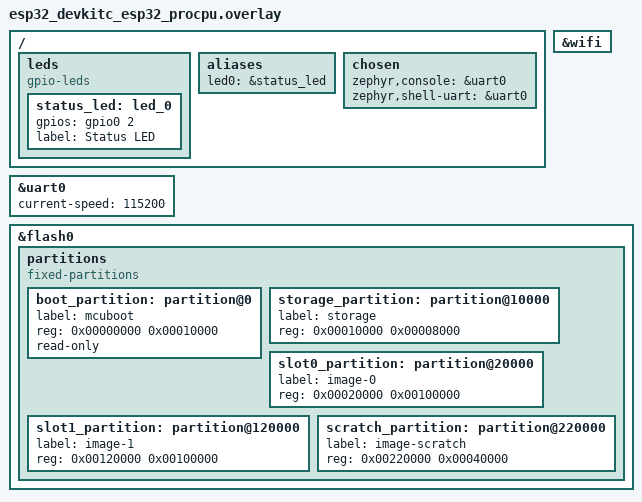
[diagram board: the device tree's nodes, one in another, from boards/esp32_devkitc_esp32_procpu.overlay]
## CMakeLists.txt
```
# SPDX-License-Identifier: Apache-2.0

cmake_minimum_required(VERSION 3.20.0)

find_package(Zephyr REQUIRED HINTS $ENV{ZEPHYR_BASE})
#find_package(Sysbuild REQUIRED)
#project(sample_with_mcuboot)

# Verify that this sample is built through sysbuild to ensure MCUboot is
# automatically included and that sample specific MCUboot configurations are
# used when building MCUboot.
test_sysbuild()

project(zephyr_project)
add_subdirectory(app)
#add_subdirectory(sysbuild/mcuboot mcuboot)
```

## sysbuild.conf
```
# Enable MCUboot
SB_CONFIG_BOOTLOADER_MCUBOOT=y

# Sign images automatically
SB_CONFIG_BOOT_SIGNATURE_TYPE_RSA=y
#SB_CONFIG_BOOT_SIGNATURE_KEY_FILE="peter_pan.pem"

#CONFIG_BOOT_SIGNATURE_KEY_FILE="peter_pan.pem"
```

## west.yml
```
manifest:
  defaults:
    remote: upstream
  remotes:
    - name: upstream
      url-base: https://github.com/zephyrproject-rtos
    - name: mcuboot
      url-base: https://github.com/mcu-tools
  projects:
    - name: zephyr
      remote: upstream
      revision: main
      import: true
    - name: mcuboot
      remote: mcuboot
      revision: main  # oder v2.1.0 für stabile Version
      path: bootloader/mcuboot
    - name: tinycrypt
      path: modules/crypto/tinycrypt
      remote: mcu-tools
      revision: main
```

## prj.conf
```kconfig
# Empty file
# CONFIG_PARTITION_MANAGER=n
```

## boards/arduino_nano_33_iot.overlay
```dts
// Device tree overlay for Arduino Nano 33 IoT

&flash0 {
    partitions {
        compatible = "fixed-partitions";
        #address-cells = <1>;
        #size-cells = <1>;

        boot_partition: partition@0 {
            label = "mcuboot";
            reg = <0x00000000 0x8000>;
        };
        
        slot0_partition: partition@8000 {
            label = "image-0";
            reg = <0x00008000 0x74000>;
        };
        
        slot1_partition: partition@7c000 {
            label = "image-1";
            reg = <0x0007c000 0x74000>;
        };
        
        scratch_partition: partition@f0000 {
            label = "image-scratch";
            reg = <0x000f0000 0x10000>;
        };
    };
};

/ {
    aliases {
        led0 = &led0;
        sw0 = &button0;
    };

    leds {
        compatible = "gpio-leds";
        led0: led_0 {
            gpios = <&porta 17 GPIO_ACTIVE_LOW>;
            label = "Yellow LED";
        };
    };

    buttons {
        compatible = "gpio-keys";
        button0: button_0 {
            gpios = <&porta 16 (GPIO_PULL_UP | GPIO_ACTIVE_LOW)>;
            label = "Push button switch";
        };
    };
};
```

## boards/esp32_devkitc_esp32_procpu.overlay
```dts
/ {
    leds {
        compatible = "gpio-leds";
        status_led: led_0 {
            gpios = <&gpio0 2 GPIO_ACTIVE_HIGH>;
            label = "Status LED";
        };
    };

    aliases {
        led0 = &status_led;
    };

    chosen {
        zephyr,console = &uart0;
        zephyr,shell-uart = &uart0;
    };
};

&uart0 {
    status = "okay";
    current-speed = <115200>;
};

&wifi {
    status = "okay";
};

/* Flash partitioning for OTA */
&flash0 {
    /delete-node/ partitions;
    partitions {
        compatible = "fixed-partitions";
        #address-cells = <1>;
        #size-cells = <1>;

        /* MCUboot bootloader - 64KB */
        boot_partition: partition@0 {
            label = "mcuboot";
            reg = <0x00000000 0x00010000>;
            read-only;
        };

        /* Storage partition - 32KB, aligned to 4KB boundary */
        storage_partition: partition@10000 {
            label = "storage";
            reg = <0x00010000 0x00008000>;
        };

        /* Application slot 0 - 1MB, aligned to 4KB boundary */
        slot0_partition: partition@20000 {
            label = "image-0";
            reg = <0x00020000 0x00100000>;
        };

        /* Application slot 1 - 1MB, aligned to 4KB boundary */
        slot1_partition: partition@120000 {
            label = "image-1";
            reg = <0x00120000 0x00100000>;
        };

        /* Scratch partition - 256KB, aligned to 4KB boundary */
        scratch_partition: partition@220000 {
            label = "image-scratch";
            reg = <0x00220000 0x00040000>;
        };
    };
};
```

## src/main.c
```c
#include <zephyr/kernel.h>
#include <zephyr/logging/log.h>
#include <zephyr/dfu/mcuboot.h>

#include "app_config.h"
#include "blinky.h"
#include "wifi_mgmt.h"
#include "ota_mgmt.h"

LOG_MODULE_REGISTER(main, LOG_LEVEL_INF);

// Define a work item for the delayed confirmation
static void confirm_work_handler(struct k_work *work);
static K_WORK_DELAYABLE_DEFINE(confirm_work, confirm_work_handler);

static void confirm_work_handler(struct k_work *work)
{
    LOG_INF("Confirming running firmware as valid.");
    if (boot_write_img_confirmed() != 0) {
        LOG_ERR("Failed to confirm image!");
    } else {
        LOG_INF("Image confirmed.");
    }
}

/* OTA status callback */
static void ota_status_changed(ota_status_t status)
{
    switch (status) {
    case OTA_STATUS_CHECKING:
        LOG_INF("OTA: Checking for updates...");
        break;
    case OTA_STATUS_UPDATE_AVAILABLE:
        LOG_INF("OTA: Update available, preparing download");
        break;
    case OTA_STATUS_DOWNLOADING:
        LOG_INF("OTA: Downloading firmware update");
        break;
    case OTA_STATUS_DOWNLOAD_COMPLETE:
        LOG_INF("OTA: Download complete, preparing to apply");
        break;
    case OTA_STATUS_APPLYING:
        LOG_INF("OTA: Applying update, device will reboot");
        break;
    case OTA_STATUS_ERROR:
        LOG_ERR("OTA: Error occurred, code: %d", ota_get_last_error());
        break;
    default:
        break;
    }
}

int main(void)
{
    char version[16];
    ota_get_current_version(version, sizeof(version));
    
    // ... initializations ...
    LOG_INF("Starting ESP32 Blinky OTA v%s", version);
    
    // Check for confirmation status right away
    if (boot_is_img_confirmed() == 0) {
        LOG_INF("Running new firmware in TEST mode. Scheduling confirmation in 30s.");
        k_work_schedule(&confirm_work, K_SECONDS(30));
    }

    // Initialize your subsystems AFTER the check
    ota_register_status_callback(ota_status_changed);
    // The ota_mgmt_init will be called by SYS_INIT

    LOG_INF("Main loop");
    while (1) {
        k_sleep(K_SECONDS(5));
        
        char ip_str[16];
        int result = wifi_get_ip_address_public(ip_str, sizeof(ip_str));
        if (result == 0) {
            LOG_INF("IP: %s", ip_str);
        } else {
            LOG_INF("No IP");
        }
    }
    
    return 0;
}
```

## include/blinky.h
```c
#ifndef BLINKY_H
#define BLINKY_H

#include <zephyr/kernel.h>

/* Blink interval in milliseconds */
#define BLINK_INTERVAL_MS 1000

/**
 * @brief Initialize LED subsystem
 * 
 * This function is called automatically during system initialization.
 * 
 * @return 0 on success, negative error code on failure
 */
int blinky_init(void);

#endif /* BLINKY_H */
```

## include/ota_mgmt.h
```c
#ifndef OTA_MGMT_H
#define OTA_MGMT_H

#include <zephyr/kernel.h>
#include <stdint.h>
#include <stdbool.h>

#ifdef __cplusplus
extern "C" {
#endif

/**
 * @brief Initialize OTA management subsystem
 * 
 * This function is called automatically during system initialization.
 * 
 * @return 0 on success, negative error code on failure
 */
int ota_mgmt_init(void);

#ifdef __cplusplus
}
#endif

#endif /* OTA_MGMT_H */
```

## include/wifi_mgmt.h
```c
#ifndef WIFI_MGMT_H
#define WIFI_MGMT_H

#include <stdbool.h>

#ifdef __cplusplus
extern "C" {
#endif

/**
 * @brief Check if WiFi is connected
 * 
 * @return true if WiFi is connected, false otherwise
 */
bool wifi_is_connected(void);

int wifi_get_ip_address_public(char *ip_str, size_t len);

#ifdef __cplusplus
}
#endif

#endif /* WIFI_MGMT_H */
```

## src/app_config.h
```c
#ifndef APP_CONFIG_H
#define APP_CONFIG_H

/* Application Configuration */
#define APP_NAME "ESP32_BLINKY_OTA"
#define APP_VERSION_MAJOR 1
#define APP_VERSION_MINOR 0
#define APP_VERSION_PATCH 13

/* LED Configuration */
#define LED_BLINK_INTERVAL_MS 1000
#define LED_FAST_BLINK_MS 100
#define LED_SLOW_BLINK_MS 2000
#define LED_ERROR_PATTERN 250  // Fast blink for errors

/* WiFi Configuration */
#define WIFI_SSID " :)"
#define WIFI_PSK "Schaezler17"

/* OTA Server Configuration */
#define OTA_SERVER_HOST "192.168.2.86"  // Replace with your server IP
#define OTA_SERVER_PORT 8080
#define OTA_VERSION_URL "/api/version"
#define OTA_FIRMWARE_URL "/api/firmware"

/* OTA Update Configuration */
#define OTA_CHECK_INTERVAL_SEC 3600  // Check for updates every hour
#define OTA_MAX_DOWNLOAD_RETRIES 3
#define OTA_DOWNLOAD_TIMEOUT_MS 30000

#endif /* APP_CONFIG_H */
```

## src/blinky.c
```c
#include <zephyr/kernel.h>
#include <zephyr/drivers/gpio.h>
#include <zephyr/init.h>
#include <zephyr/logging/log.h>

#include "blinky.h"

LOG_MODULE_REGISTER(blinky, LOG_LEVEL_INF);

#define LED0_NODE DT_ALIAS(led0)
static const struct gpio_dt_spec led = GPIO_DT_SPEC_GET(LED0_NODE, gpios);

/* Work item for LED control */
static struct k_work_delayable blink_work;
static uint8_t led_state = 0;

static void blink_work_handler(struct k_work *work)
{
    ARG_UNUSED(work);
    
    /* Toggle LED */
    gpio_pin_set_dt(&led, led_state);
    led_state ^= 1;
    
    /* Reschedule with fixed interval */
    k_work_schedule(&blink_work, K_MSEC(BLINK_INTERVAL_MS));
}

int blinky_init(void)
{
    if (!device_is_ready(led.port)) {
        LOG_ERR("LED device not ready");
        return -ENODEV;
    }

    int ret = gpio_pin_configure_dt(&led, GPIO_OUTPUT_ACTIVE);
    if (ret < 0) {
        LOG_ERR("Failed to configure LED GPIO: %d", ret);
        return ret;
    }

    /* Initialize work */
    k_work_init_delayable(&blink_work, blink_work_handler);
    
    /* Start blinking */
    k_work_schedule(&blink_work, K_MSEC(BLINK_INTERVAL_MS));

    LOG_INF("Blinky subsystem initialized - blinking every %d ms", BLINK_INTERVAL_MS);
    return 0;
}

/* Auto-initialize at APPLICATION level */
SYS_INIT(blinky_init, APPLICATION, CONFIG_APPLICATION_INIT_PRIORITY);
```

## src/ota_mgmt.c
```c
#include <zephyr/kernel.h>
#include <zephyr/net/socket.h>
#include <zephyr/storage/flash_map.h>
#include <zephyr/dfu/mcuboot.h>
#include <zephyr/storage/stream_flash.h>
#include <zephyr/sys/reboot.h>
#include <zephyr/logging/log.h>
#include <zephyr/init.h>
#include <zephyr/net/http/client.h>
#include <zephyr/net/net_ip.h>
#include <zephyr/data/json.h>
#include <zephyr/drivers/watchdog.h>
#include <string.h>
#include "wifi_mgmt.h"
#include "app_config.h"
#include "ota_mgmt.h"
#include "blinky.h"
#include <zephyr/devicetree.h>


LOG_MODULE_REGISTER(ota_mgmt, LOG_LEVEL_INF);

#define FLASH_AREA_IMAGE_SECONDARY DT_FIXED_PARTITION_ID(DT_NODELABEL(slot1_partition))


/* OTA state variables */
static struct k_work_delayable ota_check_work;
static struct stream_flash_ctx flash_ctx;
static uint8_t stream_buffer[1024]; /* Buffer for stream_flash */
static ota_status_t current_status = OTA_STATUS_IDLE;
static ota_error_t last_error = OTA_ERR_NONE;
static void (*status_callback)(ota_status_t) = NULL;

/* HTTP client context */
static struct http_request http_req;
static uint8_t http_recv_buf[1024];
static int64_t content_length = 0;
static size_t total_downloaded = 0;
static bool headers_complete = false;
static int retry_count = 0;
static int http_sock = -1;

/* Watchdog */
static const struct device *wdt;
static int wdt_channel_id = -1;

/* Version parsing from JSON */
struct version_info {
    const char *version;
    int size;
};

static struct json_obj_descr version_descr[] = {
    JSON_OBJ_DESCR_PRIM(struct version_info, version, JSON_TOK_STRING),
    JSON_OBJ_DESCR_PRIM(struct version_info, size, JSON_TOK_NUMBER),
};

/* Forward declarations */
static void ota_check_work_handler(struct k_work *work);
static int perform_update(void);
static void update_status(ota_status_t new_status);
static int apply_update(void);
static void setup_watchdog(void);
static void feed_watchdog(void);
static int create_http_socket(const char *host, int port);

/* Update OTA status and trigger callback if registered */
static void update_status(ota_status_t new_status)
{
    if (current_status != new_status) {
        current_status = new_status;
        
        /* Update LED pattern based on status */
        switch (new_status) {
        case OTA_STATUS_DOWNLOADING:
            blinky_set_interval(LED_SLOW_BLINK_MS);
            break;
        case OTA_STATUS_APPLYING:
            blinky_set_interval(LED_FAST_BLINK_MS);
            break;
        case OTA_STATUS_ERROR:
            blinky_set_interval(LED_ERROR_PATTERN);
            break;
        default:
            blinky_set_interval(LED_BLINK_INTERVAL_MS);
            break;
        }
        
        if (status_callback != NULL) {
            status_callback(new_status);
        }
    }
}

/* Set error and update status */
static void set_error(ota_error_t error)
{
    last_error = error;
    update_status(OTA_STATUS_ERROR);
}

/* Setup watchdog timer */
static void setup_watchdog(void)
{
    wdt = DEVICE_DT_GET_OR_NULL(DT_ALIAS(wdt0));
    if (!wdt || !device_is_ready(wdt)) {
        LOG_ERR("Watchdog device not found or not ready");
        return;
    }
    
    struct wdt_timeout_cfg wdt_config = {
        .window.min = 0,
        .window.max = 10000,  // 10 seconds
        .callback = NULL,
        .flags = WDT_FLAG_RESET_SOC,
    };
    
    wdt_channel_id = wdt_install_timeout(wdt, &wdt_config);
    if (wdt_channel_id < 0) {
        LOG_ERR("Watchdog install error: %d", wdt_channel_id);
        return;
    }
    
    int ret = wdt_setup(wdt, WDT_OPT_PAUSE_HALTED_BY_DBG);
    if (ret < 0) {
        LOG_ERR("Watchdog setup error: %d", ret);
        return;
    }
    
    LOG_INF("Watchdog initialized with timeout of 10 seconds");
}

/* Feed the watchdog */
static void feed_watchdog(void)
{
    if (wdt && wdt_channel_id >= 0) {
        wdt_feed(wdt, wdt_channel_id);
    }
}

/* Create HTTP socket connection */
static int create_http_socket(const char *host, int port)
{
    struct zsock_addrinfo hints, *result;
    struct sockaddr_in addr;
    int sock;
    int ret;
    
    sock = zsock_socket(AF_INET, SOCK_STREAM, IPPROTO_TCP);
    if (sock < 0) {
        LOG_ERR("Failed to create socket: %d", errno);
        return -1;
    }
    
    /* Set socket timeout */
    struct zsock_timeval timeout = {
        .tv_sec = 30,
        .tv_usec = 0,
    };
    
    zsock_setsockopt(sock, SOL_SOCKET, SO_RCVTIMEO, &timeout, sizeof(timeout));
    zsock_setsockopt(sock, SOL_SOCKET, SO_SNDTIMEO, &timeout, sizeof(timeout));
    
    /* Setup address resolution */
    memset(&hints, 0, sizeof(hints));
    hints.ai_family = AF_INET;
    hints.ai_socktype = SOCK_STREAM;
    
    char port_str[8];
    snprintf(port_str, sizeof(port_str), "%d", port);
    
    ret = zsock_getaddrinfo(host, port_str, &hints, &result);
    if (ret != 0) {
        LOG_ERR("Failed to resolve hostname %s: %d", host, ret);
        zsock_close(sock);
        return -1;
    }
    
    /* Connect */
    ret = zsock_connect(sock, result->ai_addr, result->ai_addrlen);
    zsock_freeaddrinfo(result);
    
    if (ret < 0) {
        LOG_ERR("Failed to connect to %s:%d: %d", host, port, errno);
        zsock_close(sock);
        return -1;
    }
    
    LOG_INF("Connected to %s:%d", host, port);
    return sock;
}

/* HTTP response callback */
static int http_response_cb(struct http_response *rsp, 
                           enum http_final_call final_data,
                           void *user_data)
{
    int ret = 0;
    
    /* Feed watchdog to prevent reset during download */
    feed_watchdog();
    
    /* Check if this is the first time we get body data */
    if (!headers_complete && rsp->body_frag_len > 0) {
        headers_complete = true;
        content_length = rsp->content_length;
        LOG_INF("HTTP headers complete, content length: %lld", content_length);
        
        /* If checking version, parse the JSON response */
        if (current_status == OTA_STATUS_CHECKING) {
            struct version_info version = {0};
            
            ret = json_obj_parse(rsp->body_frag_start, rsp->body_frag_len,
                               version_descr, ARRAY_SIZE(version_descr),
                               &version);
            
            if (ret > 0 && version.version) {
                LOG_INF("Server version: %s", version.version);
                
                /* Compare with current version */
                char current_ver[16];
                snprintf(current_ver, sizeof(current_ver), "%d.%d.%d", 
                        APP_VERSION_MAJOR, APP_VERSION_MINOR, APP_VERSION_PATCH);
                
                if (strcmp(version.version, current_ver) != 0) {
                    LOG_INF("New version available: %s (current: %s)",
                           version.version, current_ver);
                    update_status(OTA_STATUS_UPDATE_AVAILABLE);
                    
                    /* Start download after a short delay */
                    k_work_schedule(&ota_check_work, K_SECONDS(10));
                } else {
                    LOG_INF("Already running latest version");
                    update_status(OTA_STATUS_IDLE);
                }
            } else {
                LOG_ERR("Failed to parse version info");
                set_error(OTA_ERR_SERVER_CONNECT);
            }
            
            return 0;
        }
        
        /* If downloading firmware, initialize flash */
        if (current_status == OTA_STATUS_DOWNLOADING) {
            const struct flash_area *fa;
            
            ret = flash_area_open(FLASH_AREA_IMAGE_SECONDARY, &fa);
            if (ret) {
                LOG_ERR("Failed to open flash area: %d", ret);
                set_error(OTA_ERR_FLASH_INIT);
                return ret;
            }
            
            /* Erase the flash area before writing */
            ret = flash_area_erase(fa, 0, fa->fa_size);
            if (ret) {
                LOG_ERR("Failed to erase flash area: %d", ret);
                flash_area_close(fa);
                set_error(OTA_ERR_FLASH_INIT);
                return ret;
            }
            
            ret = stream_flash_init(&flash_ctx, fa->fa_dev, stream_buffer,
                                  sizeof(stream_buffer), fa->fa_off,
                                  fa->fa_size, NULL);
            
            if (ret) {
                LOG_ERR("Failed to init stream flash: %d", ret);
                flash_area_close(fa);
                set_error(OTA_ERR_FLASH_INIT);
                return ret;
            }
            
            LOG_INF("Flash initialized for firmware download");
            total_downloaded = 0;
        }
    }
    
    /* Process body data for firmware download */
    if (headers_complete && current_status == OTA_STATUS_DOWNLOADING && 
        rsp->body_frag_len > 0) {
        
        ret = stream_flash_buffered_write(&flash_ctx, 
                                        rsp->body_frag_start,
                                        rsp->body_frag_len, 
                                        final_data == HTTP_DATA_FINAL);
        
        if (ret < 0) {
            LOG_ERR("Flash write error: %d", ret);
            set_error(OTA_ERR_FLASH_WRITE);
            return ret;
        }
        
        total_downloaded += rsp->body_frag_len;
        
        if (total_downloaded % 4096 == 0 || final_data == HTTP_DATA_FINAL) {
            double progress = (double)total_downloaded * 100.0 / content_length;
            LOG_INF("Downloaded: %zu bytes (%.1f%%)", total_downloaded, progress);
        }
        
        /* Check if download is complete */
        if (final_data == HTTP_DATA_FINAL) {
            LOG_INF("Firmware download complete: %zu bytes", total_downloaded);
            update_status(OTA_STATUS_DOWNLOAD_COMPLETE);
            
            /* Apply update after a short delay */
            k_work_schedule(&ota_check_work, K_SECONDS(1));
        }
    }
    
    return 0;
}

/* Check for firmware updates */
static int check_for_update(void)
{
    if (!wifi_is_connected()) {
        LOG_WRN("WiFi not connected, skipping update check");
        return -ENOTCONN;
    }
    
    update_status(OTA_STATUS_CHECKING);
    
    /* Create socket connection */
    http_sock = create_http_socket(OTA_SERVER_HOST, OTA_SERVER_PORT);
    if (http_sock < 0) {
        set_error(OTA_ERR_SERVER_CONNECT);
        return -ECONNREFUSED;
    }
    
    /* Setup HTTP request for version check */
    memset(&http_req, 0, sizeof(http_req));
    
    http_req.method = HTTP_GET;
    http_req.url = OTA_VERSION_URL;
    http_req.host = OTA_SERVER_HOST;
    http_req.protocol = "HTTP/1.1";
    http_req.response = http_response_cb;
    http_req.recv_buf = http_recv_buf;
    http_req.recv_buf_len = sizeof(http_recv_buf);
    
    headers_complete = false;
    
    LOG_INF("Checking for updates at http://%s:%d%s", 
           OTA_SERVER_HOST, OTA_SERVER_PORT, OTA_VERSION_URL);
    
    int ret = http_client_req(http_sock, &http_req, 5000, NULL);
    
    /* Close socket */
    zsock_close(http_sock);
    http_sock = -1;
    
    if (ret < 0) {
        LOG_ERR("Failed to connect to update server: %d", ret);
        set_error(OTA_ERR_SERVER_CONNECT);
    }
    
    return ret;
}

/* Download and install firmware update */
static int perform_update(void)
{
    LOG_INF("Tryning to download firmware");
    if (!wifi_is_connected()) {
        LOG_WRN("WiFi not connected, cannot download update");
        return -ENOTCONN;
    }
    
    update_status(OTA_STATUS_DOWNLOADING);
    
    /* Create socket connection */
    http_sock = create_http_socket(OTA_SERVER_HOST, OTA_SERVER_PORT);
    if (http_sock < 0) {
        set_error(OTA_ERR_SERVER_CONNECT);
        return -ECONNREFUSED;
    }
    
    /* Setup HTTP request for firmware download */
    memset(&http_req, 0, sizeof(http_req));
    
    http_req.method = HTTP_GET;
    http_req.url = OTA_FIRMWARE_URL;
    http_req.host = OTA_SERVER_HOST;
    http_req.protocol = "HTTP/1.1";
    http_req.response = http_response_cb;
    http_req.recv_buf = http_recv_buf;
    http_req.recv_buf_len = sizeof(http_recv_buf);
    
    headers_complete = false;
    
    LOG_INF("Downloading firmware from http://%s:%d%s", 
           OTA_SERVER_HOST, OTA_SERVER_PORT, OTA_FIRMWARE_URL);
    
    int ret = http_client_req(http_sock, &http_req, OTA_DOWNLOAD_TIMEOUT_MS, NULL);
    
    /* Close socket */
    zsock_close(http_sock);

    http_sock = -1;
    
    if (ret < 0) {
        LOG_ERR("Failed to download firmware: %d", ret);
        set_error(OTA_ERR_DOWNLOAD_FAILED);
        
        /* Retry logic */
        if (++retry_count < OTA_MAX_DOWNLOAD_RETRIES) {
            LOG_INF("Retrying download (%d/%d) in 5 seconds...", 
                   retry_count + 1, OTA_MAX_DOWNLOAD_RETRIES);
            k_work_schedule(&ota_check_work, K_SECONDS(5));
        } else {
            LOG_ERR("Max retry attempts reached, giving up");
            retry_count = 0;
            update_status(OTA_STATUS_IDLE);
        }
    } else {
        /* Reset retry counter on success */
        retry_count = 0;
    }
    
    return ret;
}

/* Apply downloaded update */
static int apply_update(void)
{
    update_status(OTA_STATUS_APPLYING);
    
    /* Mark image for testing */
    int ret = boot_request_upgrade(BOOT_UPGRADE_TEST);
    
    if (ret != 0) {
        LOG_ERR("Failed to request upgrade: %d", ret);
        set_error(OTA_ERR_APPLY_UPDATE);
        return ret;
    }
    
    LOG_INF("Update ready - rebooting in 3 seconds");
    k_sleep(K_SECONDS(3));
    sys_reboot(SYS_REBOOT_WARM);
    
    return 0; /* Will never reach here */
}

/* OTA check work handler */
static void ota_check_work_handler(struct k_work *work)
{
    ARG_UNUSED(work);
    
    /* Feed watchdog */
    feed_watchdog();
    
    switch (current_status) {
    case OTA_STATUS_IDLE:
        check_for_update();
        break;
        
    case OTA_STATUS_UPDATE_AVAILABLE:
        perform_update();
        break;
        
    case OTA_STATUS_DOWNLOAD_COMPLETE:
        apply_update();
        break;
        
    default:
        break;
    }
}

/* Public functions */
int ota_check_for_update(void)
{
    if (current_status != OTA_STATUS_IDLE) {
        LOG_WRN("OTA operation already in progress");
        return -EBUSY;
    }
    
    return check_for_update();
}

ota_status_t ota_get_status(void)
{
    return current_status;
}

ota_error_t ota_get_last_error(void)
{
    return last_error;
}

void ota_register_status_callback(void (*callback)(ota_status_t status))
{
    status_callback = callback;
}

int ota_get_current_version(char *version, size_t len)
{
    if (!version || len < 8) {
        return -EINVAL;
    }
    
    snprintf(version, len, "%d.%d.%d", 
             APP_VERSION_MAJOR, APP_VERSION_MINOR, APP_VERSION_PATCH);
    
    return 0;
}

int ota_confirm_image(void)
{
    return boot_write_img_confirmed();
}

int ota_mgmt_init(void)
{
    /* Initialize OTA check work */
    k_work_init_delayable(&ota_check_work, ota_check_work_handler);
    
    /* Setup watchdog */
    setup_watchdog();
    
    /* Check if we're running a test image */
    if (boot_is_img_confirmed() == 0) {
        LOG_INF("Running unconfirmed image - waiting for validation");
        
        /* Schedule image confirmation after 30 seconds if everything works */
        k_work_schedule(&ota_check_work, K_SECONDS(15));
    } else {
        /* Start first update check after 60 seconds */
        k_work_schedule(&ota_check_work, K_SECONDS(35));
    }
    
    LOG_INF("OTA management subsystem initialized");
    return 0;
}

/* Auto-initialize at APPLICATION level */
SYS_INIT(ota_mgmt_init, APPLICATION, CONFIG_APPLICATION_INIT_PRIORITY);
```

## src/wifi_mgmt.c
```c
#include <zephyr/kernel.h>
#include <zephyr/net/net_if.h>
#include <zephyr/net/wifi_mgmt.h>
#include <zephyr/net/net_event.h>
#include <zephyr/net/net_ip.h>
#include <zephyr/net/dhcpv4.h>  // DHCP Header hinzufügen
#include <zephyr/net/socket.h>  // Für Socket-Funktionen
#include <zephyr/logging/log.h>
#include <zephyr/init.h>
#include <string.h>
#include "app_config.h"

LOG_MODULE_REGISTER(wifi_mgmt, LOG_LEVEL_INF);

static struct net_mgmt_event_callback wifi_cb;
static struct k_work_delayable wifi_connect_work;
static bool wifi_connected = false;

/* Forward declarations */
static int wifi_get_ip_address(char *ip_str, size_t len);
static void wifi_connect_work_handler(struct k_work *work);

/* Interface setup nach WiFi-Connect */
static void setup_network_interface(struct net_if *iface)
{
    if (!iface) {
        LOG_ERR("No interface provided");
        return;
    }
    
    LOG_INF("=== Setting up network interface ===");
    
    /* Interface Status prüfen */
    LOG_INF("Interface up before: %s", net_if_is_up(iface) ? "YES" : "NO");
    LOG_INF("Interface admin up: %s", net_if_is_admin_up(iface) ? "YES" : "NO");
    
    /* Interface explizit aktivieren */
    if (!net_if_is_up(iface)) {
        LOG_INF("Bringing interface UP");
        net_if_up(iface);
    }
    
    /* DHCP explizit starten */
    LOG_INF("Starting DHCP client");
    net_dhcpv4_start(iface);
    
    LOG_INF("Interface up after: %s", net_if_is_up(iface) ? "YES" : "NO");
}

static int test_network_connectivity(void)
{
    struct sockaddr_in addr;
    int sock;
    int ret;
    
    /* Versuche Verbindung zu Google DNS (8.8.8.8) */
    sock = zsock_socket(AF_INET, SOCK_STREAM, IPPROTO_TCP);
    if (sock < 0) {
        LOG_ERR("Failed to create socket: %d", errno);
        return -1;
    }
    
    addr.sin_family = AF_INET;
    addr.sin_port = htons(53);  // DNS Port
    zsock_inet_pton(AF_INET, "8.8.8.8", &addr.sin_addr);
    
    LOG_INF("Testing connectivity to 8.8.8.8:53...");
    
    ret = zsock_connect(sock, (struct sockaddr *)&addr, sizeof(addr));
    zsock_close(sock);
    
    if (ret == 0) {
        LOG_INF("✓ Internet connectivity confirmed!");
        return 0;
    } else {
        LOG_WRN("✗ Internet connectivity failed: %d", ret);
        return -1;
    }
}

/* IP-Adresse Debug-Funktion */
static int wifi_get_ip_address(char *ip_str, size_t len)
{
    struct net_if *iface = net_if_get_default();
    
    if (!iface || !wifi_connected) {
        return -2;
    }
    
    LOG_INF("=== IP Address Debug ===");
    LOG_INF("Interface up: %s", net_if_is_up(iface) ? "YES" : "NO");
    
    /* Alle IPv4-Adressen durchsuchen */
    for (int state = 0; state < 5; state++) {
        struct in_addr *addr = net_if_ipv4_get_global_addr(iface, state);
        if (addr) {
            char temp_ip[16];
            net_addr_ntop(AF_INET, addr, temp_ip, sizeof(temp_ip));
            LOG_INF("Found IP (state %d): %s", state, temp_ip);
            
            /* Jede gefundene IP verwenden */
            strncpy(ip_str, temp_ip, len);
            ip_str[len-1] = '\0';
            return 0;
        }
    }
    
    LOG_WRN("No IP addresses found");
    return -1;
}

/* WiFi connection work handler */
static void wifi_connect_work_handler(struct k_work *work)
{
    ARG_UNUSED(work);
    
    /* Wenn schon verbunden, IP-Adresse checken */
    if (wifi_connected) {
        LOG_INF("WiFi connected - checking for IP address...");
        char ip_str[16];
        int result = wifi_get_ip_address(ip_str, sizeof(ip_str));
        
        if (result == 0) {
            LOG_INF("*** IP address obtained: %s ***", ip_str);

            /* Netzwerk-Konnektivität testen */
            if (test_network_connectivity() == 0) {
                LOG_INF("*** Full network connectivity confirmed! ***");
            }

            return; // Erfolgreich - fertig
        } else {
            LOG_INF("Still waiting for IP address... (retry in 5s)");
            k_work_schedule(&wifi_connect_work, K_SECONDS(5));
            return;
        }
    }
    
    /* WiFi-Connection versuchen */
    struct net_if *iface = net_if_get_default();
    if (!iface) {
        LOG_ERR("WiFi interface not available");
        k_work_schedule(&wifi_connect_work, K_SECONDS(5));
        return;
    }
    
    struct wifi_connect_req_params params = {
        .ssid = WIFI_SSID,
        .ssid_length = strlen(WIFI_SSID),
        .psk = WIFI_PSK,
        .psk_length = strlen(WIFI_PSK),
        .channel = WIFI_CHANNEL_ANY,
        .security = WIFI_SECURITY_TYPE_PSK,
    };
    
    LOG_INF("Attempting WiFi connection to: %s", WIFI_SSID);
    
    int ret = net_mgmt(NET_REQUEST_WIFI_CONNECT, iface,
                      &params, sizeof(params));
    
    if (ret) {
        LOG_ERR("WiFi connection request failed: %d", ret);
        k_work_schedule(&wifi_connect_work, K_SECONDS(10));
    }
}

/* WiFi event handler */
static void wifi_event_handler(struct net_mgmt_event_callback *cb,
                              uint64_t mgmt_event, struct net_if *iface)
{
    ARG_UNUSED(cb);
    
    switch (mgmt_event) {
    case NET_EVENT_WIFI_CONNECT_RESULT:
        LOG_INF("*** WiFi connected successfully ***");
        wifi_connected = true;
        
        /* Network Interface setup */
        setup_network_interface(iface);
        
        /* Etwas länger warten für DHCP */
        k_work_schedule(&wifi_connect_work, K_SECONDS(10));
        break;
        
    case NET_EVENT_WIFI_DISCONNECT_RESULT:
        LOG_WRN("WiFi disconnected - will retry");
        wifi_connected = false;
        k_work_schedule(&wifi_connect_work, K_SECONDS(5));
        break;
        
    default:
        break;
    }
}

/* Public functions */
bool wifi_is_connected(void)
{
    return wifi_connected;
}

int wifi_get_ip_address_public(char *ip_str, size_t len)
{
    return wifi_get_ip_address(ip_str, len);
}

static int wifi_mgmt_init(void)
{
    /* Setup WiFi event callback */
    net_mgmt_init_event_callback(&wifi_cb, wifi_event_handler,
                                NET_EVENT_WIFI_CONNECT_RESULT |
                                NET_EVENT_WIFI_DISCONNECT_RESULT);
    net_mgmt_add_event_callback(&wifi_cb);
    
    /* Initialize connection work */
    k_work_init_delayable(&wifi_connect_work, wifi_connect_work_handler);
    
    /* Start initial connection attempt */
    k_work_schedule(&wifi_connect_work, K_SECONDS(2));
    
    LOG_INF("WiFi management subsystem initialized");
    return 0;
}

/* Auto-initialize after networking */
SYS_INIT(wifi_mgmt_init, APPLICATION, CONFIG_APPLICATION_INIT_PRIORITY);
```
